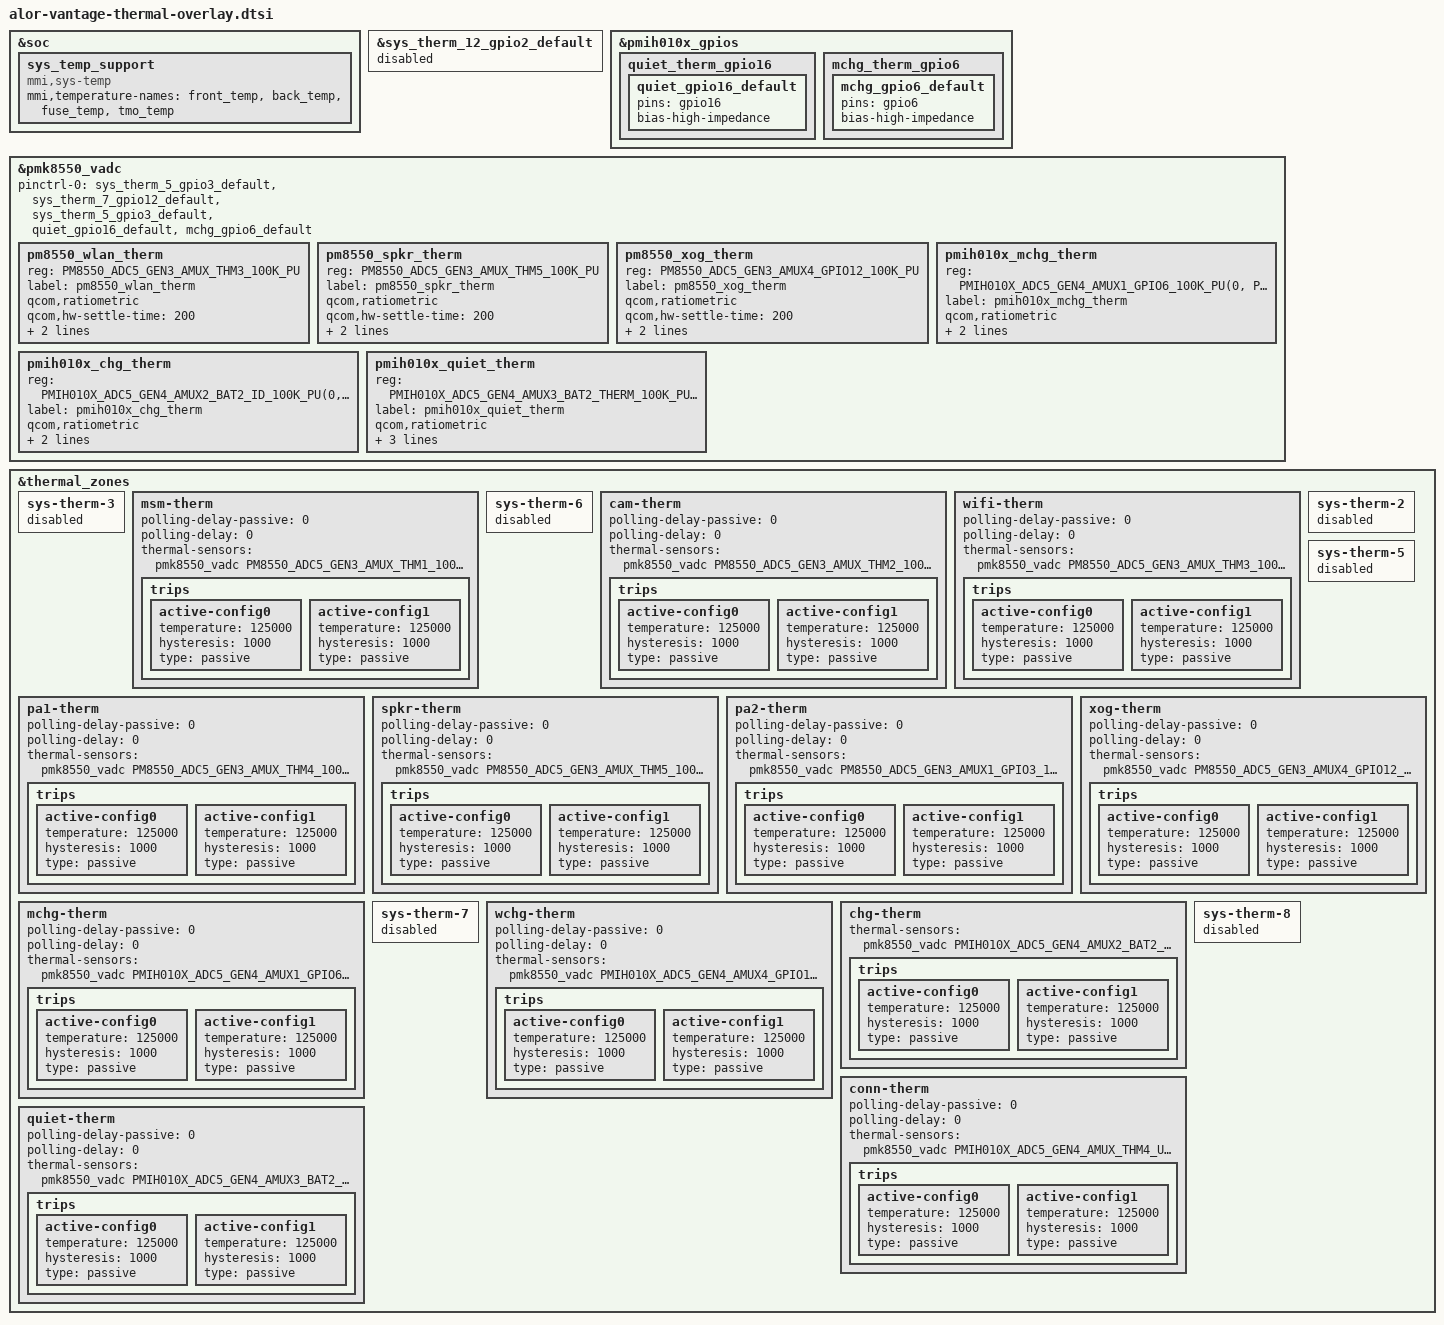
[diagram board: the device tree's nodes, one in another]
/* Copyright (c) 2025 Motorola Mobility LLC. All rights reserved.
 *
 * This program is free software; you can redistribute it and/or modify
 * it under the terms of the GNU General Public License version 2 and
 * only version 2 as published by the Free Software Foundation.
 *
 * This program is distributed in the hope that it will be useful,
 * but WITHOUT ANY WARRANTY; without even the implied warranty of
 * MERCHANTABILITY or FITNESS FOR A PARTICULAR PURPOSE.  See the
 * GNU General Public License for more details.
 */

&soc {
	sys_temp_support {
		compatible = "mmi,sys-temp";
		mmi,temperature-names = "front_temp",
			"back_temp",
			"fuse_temp",
			"tmo_temp";
		status = "ok";
	};
};

&sys_therm_12_gpio2_default {
	status = "disabled";
};

&pmih010x_gpios {
	quiet_therm_gpio16 {
		quiet_gpio16_default: quiet_gpio16_default {
			pins = "gpio16";
			bias-high-impedance;
		};
	};

    mchg_therm_gpio6 {
		mchg_gpio6_default: mchg_gpio6_default {
			pins = "gpio6";
			bias-high-impedance;
		};
	};
};

&pmk8550_vadc {
	pinctrl-0 = <&sys_therm_5_gpio3_default>,
			<&sys_therm_7_gpio12_default>,
			<&sys_therm_5_gpio3_default>,
			<&quiet_gpio16_default>,
            <&mchg_gpio6_default>;
	pinctrl-names = "default";

	pm8550_wlan_therm {
		reg = <PM8550_ADC5_GEN3_AMUX_THM3_100K_PU>;
		label = "pm8550_wlan_therm";
		qcom,ratiometric;
		qcom,hw-settle-time = <200>;
		qcom,pre-scaling = <1 1>;
		qcom,adc-tm-type = <1>;
	};

	pm8550_spkr_therm {
		reg = <PM8550_ADC5_GEN3_AMUX_THM5_100K_PU>;
		label = "pm8550_spkr_therm";
		qcom,ratiometric;
		qcom,hw-settle-time = <200>;
		qcom,pre-scaling = <1 1>;
		qcom,adc-tm-type = <1>;
	};

	pm8550_xog_therm {
		reg = <PM8550_ADC5_GEN3_AMUX4_GPIO12_100K_PU>;
		label = "pm8550_xog_therm";
		qcom,ratiometric;
		qcom,hw-settle-time = <200>;
		qcom,pre-scaling = <1 1>;
		qcom,adc-tm-type = <1>;
	};

	pmih010x_mchg_therm {
		reg = <PMIH010X_ADC5_GEN4_AMUX1_GPIO6_100K_PU(0, PMIH010X_SID)>;
		label = "pmih010x_mchg_therm";
		qcom,ratiometric;
		qcom,hw-settle-time = <200>;
		qcom,adc-tm-type = <1>;
	};

	pmih010x_chg_therm {
		reg = <PMIH010X_ADC5_GEN4_AMUX2_BAT2_ID_100K_PU(0, PMIH010X_SID)>;
		label = "pmih010x_chg_therm";
		qcom,ratiometric;
		qcom,hw-settle-time = <200>;
		qcom,adc-tm-type = <1>;
	};

/*
	pmih010x_batt_therm {
		reg = <PMIH010X_ADC5_GEN4_AMUX_THM1_BAT_THERM_100K_PU(0, PMIH010X_SID)>;
		label = "pmih010x_batt_therm";
		qcom,ratiometric;
		qcom,hw-settle-time = <200>;
		qcom,adc-tm-type = <1>;
	};
*/

	pmih010x_quiet_therm {
		reg = <PMIH010X_ADC5_GEN4_AMUX3_BAT2_THERM_100K_PU(0, PMIH010X_SID)>;
		label = "pmih010x_quiet_therm";
		qcom,ratiometric;
		qcom,pre-scaling = <1 1>;
		qcom,adc-tm-type = <1>;
		qcom,adc5-gen4;
	};
};

&thermal_zones {

/*
	sys-therm-0 {
		status = "disabled";
	};
	xo-therm {
		polling-delay-passive = <0>;
		polling-delay = <0>;
		thermal-sensors = <&pmk8550_vadc PMK8550_ADC5_GEN3_AMUX_THM1_XO_THERM_100K_PU>;

		trips {
			active-config0 {
				temperature = <125000>;
				hysteresis = <1000>;
				type = "passive";
			};

			active-config1 {
				temperature = <125000>;
				hysteresis = <1000>;
				type = "passive";
			};
		};
	};
*/
	sys-therm-3 {
		status = "disabled";
	};
	msm-therm {
		polling-delay-passive = <0>;
		polling-delay = <0>;
		thermal-sensors = <&pmk8550_vadc PM8550_ADC5_GEN3_AMUX_THM1_100K_PU>;

		trips {
			active-config0 {
				temperature = <125000>;
				hysteresis = <1000>;
				type = "passive";
			};

			active-config1 {
				temperature = <125000>;
				hysteresis = <1000>;
				type = "passive";
			};
		};
	};

	sys-therm-6 {
		status = "disabled";
	};
	cam-therm {
		polling-delay-passive = <0>;
		polling-delay = <0>;
		thermal-sensors = <&pmk8550_vadc PM8550_ADC5_GEN3_AMUX_THM2_100K_PU>;

		trips {
			active-config0 {
				temperature = <125000>;
				hysteresis = <1000>;
				type = "passive";
			};

			active-config1 {
				temperature = <125000>;
				hysteresis = <1000>;
				type = "passive";
			};
		};
	};

	wifi-therm {
		polling-delay-passive = <0>;
		polling-delay = <0>;
		thermal-sensors = <&pmk8550_vadc PM8550_ADC5_GEN3_AMUX_THM3_100K_PU>;

		trips {
			active-config0 {
				temperature = <125000>;
				hysteresis = <1000>;
				type = "passive";
			};

			active-config1 {
				temperature = <125000>;
				hysteresis = <1000>;
				type = "passive";
			};
		};
	};

	sys-therm-2 {
		status = "disabled";
	};
	pa1-therm {
		polling-delay-passive = <0>;
		polling-delay = <0>;
		thermal-sensors = <&pmk8550_vadc PM8550_ADC5_GEN3_AMUX_THM4_100K_PU>;

		trips {
			active-config0 {
				temperature = <125000>;
				hysteresis = <1000>;
				type = "passive";
			};

			active-config1 {
				temperature = <125000>;
				hysteresis = <1000>;
				type = "passive";
			};
		};
	};

	spkr-therm {
		polling-delay-passive = <0>;
		polling-delay = <0>;
		thermal-sensors = <&pmk8550_vadc PM8550_ADC5_GEN3_AMUX_THM5_100K_PU>;

		trips {
			active-config0 {
				temperature = <125000>;
				hysteresis = <1000>;
				type = "passive";
			};

			active-config1 {
				temperature = <125000>;
				hysteresis = <1000>;
				type = "passive";
			};
		};
	};

	sys-therm-5 {
		status = "disabled";
	};
	pa2-therm {
		polling-delay-passive = <0>;
		polling-delay = <0>;
		thermal-sensors = <&pmk8550_vadc PM8550_ADC5_GEN3_AMUX1_GPIO3_100K_PU>;

		trips {
			active-config0 {
				temperature = <125000>;
				hysteresis = <1000>;
				type = "passive";
			};

			active-config1 {
				temperature = <125000>;
				hysteresis = <1000>;
				type = "passive";
			};
		};
	};

	xog-therm {
		polling-delay-passive = <0>;
		polling-delay = <0>;
		thermal-sensors = <&pmk8550_vadc PM8550_ADC5_GEN3_AMUX4_GPIO12_100K_PU>;

		trips {
			active-config0 {
				temperature = <125000>;
				hysteresis = <1000>;
				type = "passive";
			};

			active-config1 {
				temperature = <125000>;
				hysteresis = <1000>;
				type = "passive";
			};
		};
	};

	mchg-therm {
		polling-delay-passive = <0>;
		polling-delay = <0>;
		thermal-sensors = <&pmk8550_vadc PMIH010X_ADC5_GEN4_AMUX1_GPIO6_100K_PU(0, PMIH010X_SID)>;

		trips {
			active-config0 {
				temperature = <125000>;
				hysteresis = <1000>;
				type = "passive";
			};

			active-config1 {
				temperature = <125000>;
				hysteresis = <1000>;
				type = "passive";
			};
		};
	};

	sys-therm-7 {
		status = "disabled";
	};
	wchg-therm {
		polling-delay-passive = <0>;
		polling-delay = <0>;
		thermal-sensors = <&pmk8550_vadc PMIH010X_ADC5_GEN4_AMUX4_GPIO12_100K_PU(0, PMIH010X_SID)>;
		trips {
			active-config0 {
				temperature = <125000>;
				hysteresis = <1000>;
				type = "passive";
			};

			active-config1 {
				temperature = <125000>;
				hysteresis = <1000>;
				type = "passive";
			};
		};
	};

	chg-therm {
		thermal-sensors = <&pmk8550_vadc PMIH010X_ADC5_GEN4_AMUX2_BAT2_ID_100K_PU(0, PMIH010X_SID)>;

		trips {
			active-config0 {
				temperature = <125000>;
				hysteresis = <1000>;
				type = "passive";
			};

			active-config1 {
				temperature = <125000>;
				hysteresis = <1000>;
				type = "passive";
			};
		};
	};

	sys-therm-8 {
		status = "disabled";
	};
	conn-therm {
		polling-delay-passive = <0>;
		polling-delay = <0>;
		thermal-sensors = <&pmk8550_vadc PMIH010X_ADC5_GEN4_AMUX_THM4_USB_THERM_100K_PU(0, PMIH010X_SID)>;
		trips {
			active-config0 {
				temperature = <125000>;
				hysteresis = <1000>;
				type = "passive";
			};

			active-config1 {
				temperature = <125000>;
				hysteresis = <1000>;
				type = "passive";
			};
		};
	};
/*
	batt-therm {
		thermal-sensors = <&pmk8550_vadc PMIH010X_ADC5_GEN4_AMUX_THM1_BAT_THERM_100K_PU(0, PMIH010X_SID)>;

		trips {
			active-config0 {
				temperature = <125000>;
				hysteresis = <1000>;
				type = "passive";
			};

			active-config1 {
				temperature = <125000>;
				hysteresis = <1000>;
				type = "passive";
			};
		};
	};
*/

	quiet-therm {
		polling-delay-passive = <0>;
		polling-delay = <0>;
		thermal-sensors = <&pmk8550_vadc PMIH010X_ADC5_GEN4_AMUX3_BAT2_THERM_100K_PU(0, PMIH010X_SID)>;
		trips {
			active-config0 {
				temperature = <125000>;
				hysteresis = <1000>;
				type = "passive";
			};

			active-config1 {
				temperature = <125000>;
				hysteresis = <1000>;
				type = "passive";
			};
		};
	};
/*
	sys-therm-12 {
		status = "disabled";
	};
*/
};

